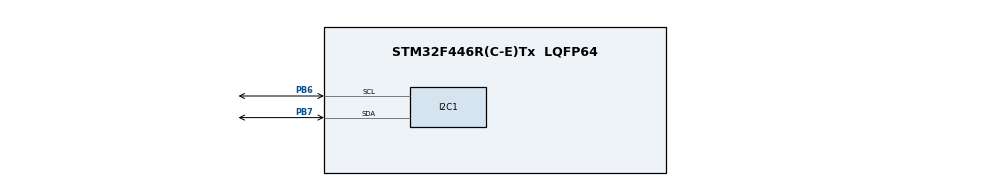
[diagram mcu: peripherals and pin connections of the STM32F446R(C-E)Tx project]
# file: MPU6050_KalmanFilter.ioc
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Mcu.Family=STM32F4
Mcu.Name=STM32F446R(C-E)Tx
Mcu.Package=LQFP64
NVIC.PriorityGroup=NVIC_PRIORITYGROUP_4
PA13.Mode=Serial_Wire
PA13.Signal=SYS_JTMS-SWDIO
PA14.Mode=Serial_Wire
PA14.Signal=SYS_JTCK-SWCLK
PB6.Mode=I2C
PB6.Signal=I2C1_SCL
PB7.Mode=I2C
PB7.Signal=I2C1_SDA
ProjectManager.HeapSize=0x200
ProjectManager.StackSize=0x400
ProjectManager.TargetToolchain=STM32CubeIDE
RCC.CortexFreq_Value=16000000
RCC.USBFreq_Value=96000000
RCC.VCOOutputFreq_Value=192000000
board=custom

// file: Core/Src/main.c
/* USER CODE BEGIN Header */
/**
  ******************************************************************************
  * @file           : main.c
  * @brief          : Main program body
  ******************************************************************************
  * @attention
  *
  * <h2><center>&copy; Copyright (c) 2021 STMicroelectronics.
  * All rights reserved.</center></h2>
  *
  * This software component is licensed by ST under BSD 3-Clause license,
  * the "License"; You may not use this file except in compliance with the
  * License. You may obtain a copy of the License at:
  *                        opensource.org/licenses/BSD-3-Clause
  *
  ******************************************************************************
  */
/* USER CODE END Header */
#include "main.h"

/* USER CODE BEGIN Includes */
#include "mpu6050.h"
#include "i2c.h"
/* USER CODE END Includes */

extern I2C_HandleTypeDef hi2c1;

/* USER CODE BEGIN PV */
MPU6050_t MPU6050_1;
MPU6050_t MPU6050_2;
/* USER CODE END PV */

void SystemClock_Config(void);
static void MX_GPIO_Init(void);
//static void MX_I2C1_Init(void);

/* USER CODE BEGIN 0 */

float AngX_1, AngY_1, AngX_2, AngY_2, diff_X, diff_Y, meanX, meanY, diffToMean_X1, diffToMean_X2, diffToMean_Y1, diffToMean_Y2;

/* USER CODE END 0 */

int main(void)
{

  /* MCU Configuration--------------------------------------------------------*/

  /* Reset of all peripherals, Initializes the Flash interface and the Systick. */
  HAL_Init();

  /* Configure the system clock */
  SystemClock_Config();

  /* Initialize all configured peripherals */
  MX_GPIO_Init();
  MX_I2C1_Init();

  /* Infinite loop */
  /* USER CODE BEGIN WHILE */
  while (1)
  {
	  MPU6050_Read_All(&hi2c1, &MPU6050_1);
	  MPU6050_Read_All(&hi2c2, &MPU6050_2);

	  AngX_1 = MPU6050_1.KalmanAngleX;
	  AngY_1 = MPU6050_1.KalmanAngleY;

	  AngX_2 = MPU6050_2.KalmanAngleX;
	  AngY_2 = MPU6050_2.KalmanAngleY;

	  diff_X = (AngX_1 - AngX_2);
	  diff_Y = (AngY_1 - AngY_2);

	  meanX = (AngX_1 + AngX_2) / 2;
	  meanY = (AngY_1 + AngY_2) / 2;

	  diffToMean_X1 = meanX - AngX_1;
	  diffToMean_X2 = meanX - AngX_2;

	  diffToMean_Y1 = meanY - AngY_1;
	  diffToMean_Y2 = meanY - AngY_2;

	  HAL_Delay (500);
    /* USER CODE END WHILE */

  }
}

void SystemClock_Config(void)
{
  RCC_OscInitTypeDef RCC_OscInitStruct = {0};
  RCC_ClkInitTypeDef RCC_ClkInitStruct = {0};

  /** Configure the main internal regulator output voltage
  */
  __HAL_RCC_PWR_CLK_ENABLE();
  __HAL_PWR_VOLTAGESCALING_CONFIG(PWR_REGULATOR_VOLTAGE_SCALE3);

  /** Initializes the RCC Oscillators according to the specified parameters
  * in the RCC_OscInitTypeDef structure.
  */
  RCC_OscInitStruct.OscillatorType = RCC_OSCILLATORTYPE_HSI;
  RCC_OscInitStruct.HSIState = RCC_HSI_ON;
  RCC_OscInitStruct.HSICalibrationValue = RCC_HSICALIBRATION_DEFAULT;
  RCC_OscInitStruct.PLL.PLLState = RCC_PLL_NONE;
  if (HAL_RCC_OscConfig(&RCC_OscInitStruct) != HAL_OK)
  {
    Error_Handler();
  }

  /** Initializes the CPU, AHB and APB buses clocks
  */
  RCC_ClkInitStruct.ClockType = RCC_CLOCKTYPE_HCLK|RCC_CLOCKTYPE_SYSCLK
                              |RCC_CLOCKTYPE_PCLK1|RCC_CLOCKTYPE_PCLK2;
  RCC_ClkInitStruct.SYSCLKSource = RCC_SYSCLKSOURCE_HSI;
  RCC_ClkInitStruct.AHBCLKDivider = RCC_SYSCLK_DIV1;
  RCC_ClkInitStruct.APB1CLKDivider = RCC_HCLK_DIV1;
  RCC_ClkInitStruct.APB2CLKDivider = RCC_HCLK_DIV1;

  if (HAL_RCC_ClockConfig(&RCC_ClkInitStruct, FLASH_LATENCY_0) != HAL_OK)
  {
    Error_Handler();
  }
}

//static void MX_I2C1_Init(void)
//{
//
//  /* USER CODE BEGIN I2C1_Init 0 */
//
//  /* USER CODE END I2C1_Init 0 */
//
//  /* USER CODE BEGIN I2C1_Init 1 */
//
//  /* USER CODE END I2C1_Init 1 */
//  hi2c1.Instance = I2C1;
//  hi2c1.Init.ClockSpeed = 100000;
//  hi2c1.Init.DutyCycle = I2C_DUTYCYCLE_2;
//  hi2c1.Init.OwnAddress1 = 0;
//  hi2c1.Init.AddressingMode = I2C_ADDRESSINGMODE_7BIT;
//  hi2c1.Init.DualAddressMode = I2C_DUALADDRESS_DISABLE;
//  hi2c1.Init.OwnAddress2 = 0;
//  hi2c1.Init.GeneralCallMode = I2C_GENERALCALL_DISABLE;
//  hi2c1.Init.NoStretchMode = I2C_NOSTRETCH_DISABLE;
//  if (HAL_I2C_Init(&hi2c1) != HAL_OK)
//  {
//    Error_Handler();
//  }
//  /* USER CODE BEGIN I2C1_Init 2 */
//
//  /* USER CODE END I2C1_Init 2 */
//
//}

static void MX_GPIO_Init(void)
{

  /* GPIO Ports Clock Enable */
  __HAL_RCC_GPIOA_CLK_ENABLE();
  __HAL_RCC_GPIOB_CLK_ENABLE();

}

void Error_Handler(void)
{
  __disable_irq();
  while (1)
  {
  }
}
